# MK70F15 register map
Vendor: Freescale Semiconductor, Inc.; Series: Kinetis_K; File version: 1.6
CPU: CM4 r0p1, little endian, no MPU, FPU, VTOR, 4 interrupt priority bits
Registers are 32-bit, read-write, reset 0x0 unless marked. A register's access mark holds for its fields unless they carry their own. Offsets are from the block's base; [hi:lo] are bit positions; {n}, {i} and the like mark numbered series.

## EWM — External Watchdog Monitor
Base 0x40061000; register names take the prefix EWM_
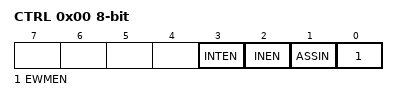
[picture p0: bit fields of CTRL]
0x00 CTRL 8-bit — Control Register
  [3] INTEN — Interrupt Enable.
  [2] INEN — Input Enable.
  [1] ASSIN — EWM_in's Assertion State Select.
  [0] EWMEN — EWM enable.
0x01 SERV 8-bit wo — Service Register
  [7:0] SERVICE — The EWM service mechanism requires the CPU to write two values to the SERV register: a first data byte of 0xB4, followed by a second data byte of 0x2C
0x02 CMPL 8-bit — Compare Low Register
  [7:0] COMPAREL — To prevent runaway code from changing this field, software should write to this field after a CPU reset even if the (default) minimum service time is required
0x03 CMPH 8-bit reset 0xFF — Compare High Register
  [7:0] COMPAREH — To prevent runaway code from changing this field, software should write to this field after a CPU reset even if the (default) maximum service time is required

## CMT — Carrier Modulator Transmitter
Base 0x40062000; register names take the prefix CMT_
0x00 CGH1 8-bit reset not defined — CMT Carrier Generator High Data Register 1
  [7:0] PH — Primary Carrier High Time Data Value
0x01 CGL1 8-bit reset not defined — CMT Carrier Generator Low Data Register 1
  [7:0] PL — Primary Carrier Low Time Data Value
0x02 CGH2 8-bit reset not defined — CMT Carrier Generator High Data Register 2
  [7:0] SH — Secondary Carrier High Time Data Value
0x03 CGL2 8-bit reset not defined — CMT Carrier Generator Low Data Register 2
  [7:0] SL — Secondary Carrier Low Time Data Value
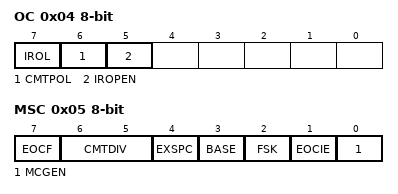
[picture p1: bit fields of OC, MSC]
0x04 OC 8-bit — CMT Output Control Register
  [7] IROL — IRO Latch Control
  [6] CMTPOL — CMT Output Polarity
    0=CMT_IRO signal is active low; 1=CMT_IRO signal is active high
  [5] IROPEN — IRO Pin Enable
    0=CMT_IRO signal disabled; 1=CMT_IRO signal enabled as output
0x05 MSC 8-bit — CMT Modulator Status and Control Register
  [7] EOCF ro — End Of Cycle Status Flag
    0=No end of modulation cycle occurrence since flag last cleared; 1=End of modulator cycle has occurred
  [6:5] CMTDIV — CMT Clock Divide Prescaler
    0=IF * 1; 1=IF * 2; 2=IF * 4; 3=IF * 8
  [4] EXSPC — Extended Space Enable
    0=Extended space disabled; 1=Extended space enabled
  [3] BASE — Baseband Enable
    0=Baseband mode disabled; 1=Baseband mode enabled
  [2] FSK — FSK Mode Select
    0=CMT operates in Time or Baseband mode; 1=CMT operates in FSK mode
  [1] EOCIE — End of Cycle Interrupt Enable
    0=CPU interrupt disabled; 1=CPU interrupt enabled
  [0] MCGEN — Modulator and Carrier Generator Enable
    0=Modulator and carrier generator disabled; 1=Modulator and carrier generator enabled
0x06 CMD1 8-bit reset not defined — CMT Modulator Data Register Mark High
  [7:0] MB — These bits control the upper mark periods of the modulator for all modes.
0x07 CMD2 8-bit reset not defined — CMT Modulator Data Register Mark Low
  [7:0] MB — These bits control the lower mark periods of the modulator for all modes.
0x08 CMD3 8-bit reset not defined — CMT Modulator Data Register Space High
  [7:0] SB — These bits control the upper space periods of the modulator for all modes.
0x09 CMD4 8-bit reset not defined — CMT Modulator Data Register Space Low
  [7:0] SB — These bits control the lower space periods of the modulator for all modes.
0x0A PPS 8-bit — CMT Primary Prescaler Register
  [3:0] PPSDIV — Primary Prescaler Divider
    {v}=Bus Clock * {v+1} (v=0..15)
0x0B DMA 8-bit — CMT Direct Memory Access
  [0] DMA — DMA Enable
    0=DMA transfer request and done are disabled; 1=DMA transfer request and done are enabled

## OSC0 — Oscillator
Base 0x40065000; register names take the prefix OSC0_
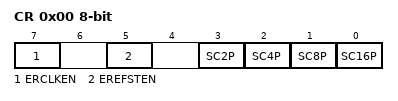
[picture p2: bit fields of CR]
0x00 CR 8-bit — OSC Control Register
  [7] ERCLKEN — External Reference Enable
    0=External reference clock is inactive; 1=External reference clock is enabled
  [5] EREFSTEN — External Reference Stop Enable
    0=External reference clock is disabled in Stop mode; 1=External reference clock stays enabled in Stop mode if ERCLKEN is set before entering Stop mode
  [3] SC2P — Oscillator 2 pF Capacitor Load Configure
    0=Disable the selection; 1=Add 2 pF capacitor to the oscillator load
  [2] SC4P — Oscillator 4 pF Capacitor Load Configure
    0=Disable the selection; 1=Add 4 pF capacitor to the oscillator load
  [1] SC8P — Oscillator 8 pF Capacitor Load Configure
    0=Disable the selection; 1=Add 8 pF capacitor to the oscillator load
  [0] SC16P — Oscillator 16 pF Capacitor Load Configure
    0=Disable the selection; 1=Add 16 pF capacitor to the oscillator load

## OSC1 — Oscillator
Base 0x400E5000; register names take the prefix OSC1_
Registers as OSC0.

## Notices in the file
Redistribution and use in source and binary forms, with or without modification,
are permitted provided that the following conditions are met:
o Redistributions of source code must retain the above copyright notice, this list
of conditions and the following disclaimer.
o Redistributions in binary form must reproduce the above copyright notice, this
list of conditions and the following disclaimer in the documentation and/or
other materials provided with the distribution.
o Neither the name of Freescale Semiconductor, Inc. nor the names of its
contributors may be used to endorse or promote products derived from this
software without specific prior written permission.
THIS SOFTWARE IS PROVIDED BY THE COPYRIGHT HOLDERS AND CONTRIBUTORS "AS IS" AND
ANY EXPRESS OR IMPLIED WARRANTIES, INCLUDING, BUT NOT LIMITED TO, THE IMPLIED
WARRANTIES OF MERCHANTABILITY AND FITNESS FOR A PARTICULAR PURPOSE ARE
DISCLAIMED. IN NO EVENT SHALL THE COPYRIGHT HOLDER OR CONTRIBUTORS BE LIABLE FOR
ANY DIRECT, INDIRECT, INCIDENTAL, SPECIAL, EXEMPLARY, OR CONSEQUENTIAL DAMAGES
(INCLUDING, BUT NOT LIMITED TO, PROCUREMENT OF SUBSTITUTE GOODS OR SERVICES;
LOSS OF USE, DATA, OR PROFITS; OR BUSINESS INTERRUPTION) HOWEVER CAUSED AND ON
ANY THEORY OF LIABILITY, WHETHER IN CONTRACT, STRICT LIABILITY, OR TORT
(INCLUDING NEGLIGENCE OR OTHERWISE) ARISING IN ANY WAY OUT OF THE USE OF THIS
SOFTWARE, EVEN IF ADVISED OF THE POSSIBILITY OF SUCH DAMAGE.
